# M3351 register map
File version: 1.0
Registers are 32-bit, read-write, reset 0x0 unless marked. A register's access mark holds for its fields unless they carry their own. Offsets are from the block's base; [hi:lo] are bit positions; {n}, {i} and the like mark numbered series; 'fields as' and 'values as' point back to an identical list.

## SCU — SCU Register Map
Base 0x4002F000
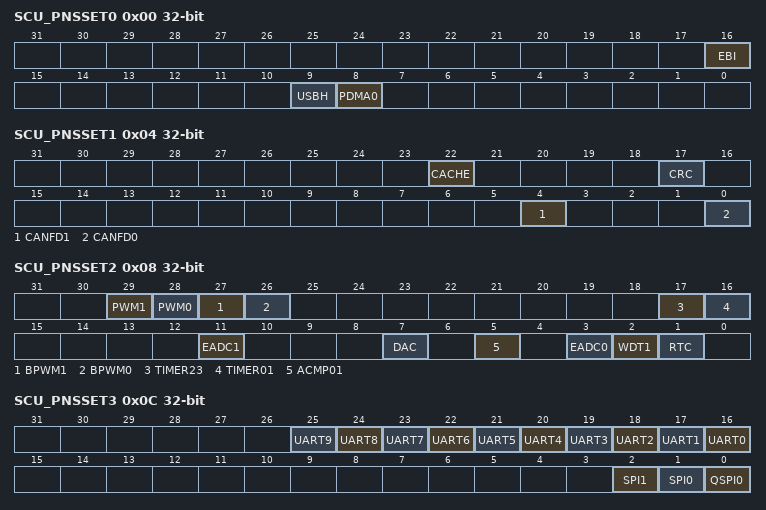
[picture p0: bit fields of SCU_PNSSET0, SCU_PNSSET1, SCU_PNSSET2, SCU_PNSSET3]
0x00 SCU_PNSSET0 — Peripheral Non-secure Attribution Set Register0 (0x4000_0000~0x4001_FFFF)
  [16] EBI — Set EBI to Non-secure State. Write 1 to set EBI to non-secure state. Note: This bit is write-protected by SCU_SCWP.
    0=EBI is a secure module (default); 1=EBI is a non-secure module
  [9] USBH — Set USBH to Non-secure State. Write 1 to set USBH to non-secure state. Note: This bit is write-protected by SCU_SCWP.
    0=USBH is a secure module (default); 1=USBH is a non-secure module
  [8] PDMA0 — Set PDMA0 to Non-secure State. Write 1 to set PDMA0 to non-secure state. Note: This bit is write-protected by SCU_SCWP.
    0=PDMA0 is a secure module (default); 1=PDMA0 is a non-secure module
0x04 SCU_PNSSET1 — Peripheral Non-secure Attribution Set Register1 (0x4002_0000~0x4003_FFFF)
  [22] CACHE — Set Cache Controller to Non-secure State. Write 1 to set Cache controller to non-secure state. Note: This bit is write-protected by SCU_SCWP.
    0=Cache controller is a secure module (default); 1=Cache controller is a non-secure module
  [17] CRC — Set CRC to Non-secure State. Write 1 to set CRC to non-secure state. Note: This bit is write-protected by SCU_SCWP.
    0=CRC is a secure module (default); 1=CRC is a non-secure module
  [4] CANFD1 — Set CANFD1 to Non-secure State. Write 1 to set CANFD1 to non-secure state. Note: This bit is write-protected by SCU_SCWP.
    0=CANFD1 is a secure module (default); 1=CANFD1 is a non-secure module
  [0] CANFD0 — Set CANFD0 to Non-secure State. Write 1 to set CANFD0 to non-secure state. Note: This bit is write-protected by SCU_SCWP.
    0=CANFD0 is a secure module (default); 1=CANFD0 is a non-secure module
0x08 SCU_PNSSET2 — Peripheral Non-secure Attribution Set Register2 (0x4004_0000~0x4005_FFFF)
  [29] PWM1 — Set PWM1 to Non-secure State. Write 1 to set PWM1 to non-secure state. Note: This bit is write-protected by SCU_SCWP.
    0=PWM1 is a secure module (default); 1=PWM1 is a non-secure module
  [28] PWM0 — Set PWM0 to Non-secure State. Write 1 to set PWM0 to non-secure state. Note: This bit is write-protected by SCU_SCWP.
    0=PWM0 is a secure module (default); 1=PWM0 is a non-secure module
  [27] BPWM1 — Set BPWM1 to Non-secure State. Write 1 to set BPWM1 to non-secure state. Note: This bit is write-protected by SCU_SCWP.
    0=BPWM1 is a secure module (default); 1=BPWM1 is a non-secure module
  [26] BPWM0 — Set BPWM0 to Non-secure State. Write 1 to set BPWM0 to non-secure state. Note: This bit is write-protected by SCU_SCWP.
    0=BPWM0 is a secure module (default); 1=BPWM0 is a non-secure module
  [17] TIMER23 — Set TIMER23 to Non-secure State. Write 1 to set TIMER23 to non-secure state. Note: This bit is write-protected by SCU_SCWP.
    0=TIMER23 is a secure module (default); 1=TIMER23 is a non-secure module
  [16] TIMER01 — Set TIMER01 to Non-secure State. Write 1 to set TIMER01 to non-secure state. Note: This bit is write-protected by SCU_SCWP.
    0=TIMER01 is a secure module (default); 1=TIMER01 is a non-secure module
  [11] EADC1 — Set EADC1 to Non-secure State. Write 1 to set EADC1 to non-secure state. Note: This bit is write-protected by SCU_SCWP.
    0=EADC1 is a secure module (default); 1=EADC1 is a non-secure module
  [7] DAC — Set DAC to Non-secure State. Write 1 to set DAC to non-secure state. Note: This bit is write-protected by SCU_SCWP.
    0=DAC is a secure module (default); 1=DAC is a non-secure module
  [5] ACMP01 — Set ACMP01 to Non-secure State. Write 1 to set ACMP01 to non-secure state. Note: This bit is write-protected by SCU_SCWP.
    0=ACMP01 is a secure module (default); 1=ACMP01 is a non-secure module
  [3] EADC0 — Set EADC0 to Non-secure State. Write 1 to set EADC0 to non-secure state. Note: This bit is write-protected by SCU_SCWP.
    0=EADC0 is a secure module (default); 1=EADC0 is a non-secure module
  [2] WDT1 — Set WDT1 to Non-secure State. Write 1 to set WDT1 to non-secure state. Note: This bit is write-protected by SCU_SCWP.
    0=WDT1 is a secure module (default); 1=WDT1 is a non-secure module
  [1] RTC — Set RTC to Non-secure State. Write 1 to set RTC to non-secure state. Note: This bit is write-protected by SCU_SCWP.
    0=RTC is a secure module (default); 1=RTC is a non-secure module
0x0C SCU_PNSSET3 — Peripheral Non-secure Attribution Set Register3 (0x4006_0000~0x4007_FFFF)
  [n+16] UART{n} (n=0..9) — Set UART{n} to Non-secure State. Write 1 to set UART{n} to non-secure state. Note: This bit is write-protected by SCU_SCWP.
    0=UART{n} is a secure module (default); 1=UART{n} is a non-secure module
  [2] SPI1 — Set SPI1 to Non-secure State. Write 1 to set SPI1 to non-secure state. Note: This bit is write-protected by SCU_SCWP.
    0=SPI1 is a secure module (default); 1=SPI1 is a non-secure module
  [1] SPI0 — Set SPI0 to Non-secure State. Write 1 to set SPI0 to non-secure state. Note: This bit is write-protected by SCU_SCWP.
    0=SPI0 is a secure module (default); 1=SPI0 is a non-secure module
  [0] QSPI0 — Set QSPI0 to Non-secure State. Write 1 to set QSPI0 to non-secure state. Note: This bit is write-protected by SCU_SCWP.
    0=QSPI0 is a secure module (default); 1=QSPI0 is a non-secure module
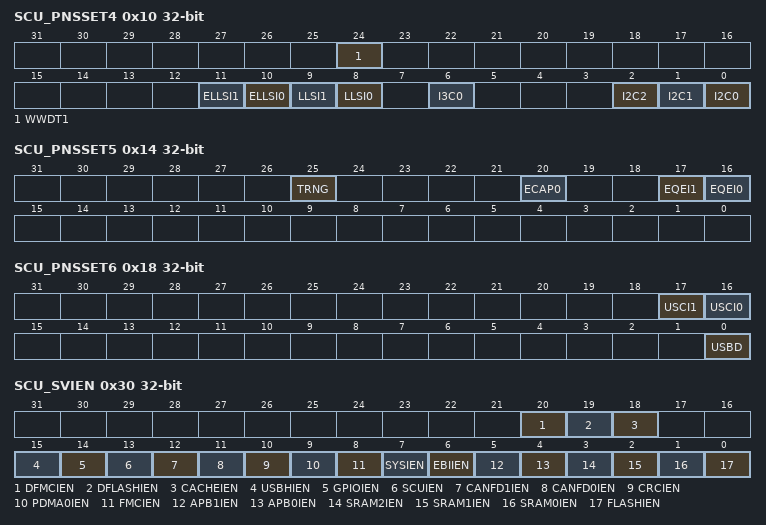
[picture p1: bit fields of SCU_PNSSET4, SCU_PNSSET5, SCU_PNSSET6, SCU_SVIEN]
0x10 SCU_PNSSET4 — Peripheral Non-secure Attribution Set Register4 (0x4008_0000~0x4009_FFFF)
  [24] WWDT1 — Set WWDT1 to Non-secure State. Write 1 to set WWDT1 to non-secure state. Note: This bit is write-protected by SCU_SCWP.
    0=WWDT1 is a secure module (default); 1=WWDT1 is a non-secure module
  [11] ELLSI1 — Set ELLSI1 to Non-secure State. Write 1 to set ELLSI1 to non-secure state. Note: This bit is write-protected by SCU_SCWP.
    0=ELLSI1 is a secure module (default); 1=ELLSI1 is a non-secure module
  [10] ELLSI0 — Set ELLSI0 to Non-secure State. Write 1 to set ELLSI0 to non-secure state. Note: This bit is write-protected by SCU_SCWP.
    0=ELLSI0 is a secure module (default); 1=ELLSI0 is a non-secure module
  [9] LLSI1 — Set LLSI1/3/5/7/9 to Non-secure State. Write 1 to set LLSI1/3/5/7/9 to non-secure state. Note: This bit is write-protected by SCU_SCWP.
    0=LLSI1/3/5/7/9 is a secure module (default); 1=LLSI1/3/5/7/9 is a non-secure module
  [8] LLSI0 — Set LLSI0/2/4/6/8 to Non-secure State. Write 1 to set LLSI0/2/4/6/8 to non-secure state. Note: This bit is write-protected by SCU_SCWP.
    0=LLSI0/2/4/6/8 is a secure module (default); 1=LLSI0/2/4/6/8 is a non-secure module
  [6] I3C0 — Set I3C0 to Non-secure State. Write 1 to set I3C0 to non-secure state. Note: This bit is write-protected by SCU_SCWP.
    0=I3C0 is a secure module (default); 1=I3C0 is a non-secure module
  [2] I2C2 — Set I2C2 to Non-secure State. Write 1 to set I2C2 to non-secure state. Note: This bit is write-protected by SCU_SCWP.
    0=I2C2 is a secure module (default); 1=I2C2 is a non-secure module
  [1] I2C1 — Set I2C1 to Non-secure State. Write 1 to set I2C1 to non-secure state. Note: This bit is write-protected by SCU_SCWP.
    0=I2C1 is a secure module (default); 1=I2C1 is a non-secure module
  [0] I2C0 — Set I2C0 to Non-secure State. Write 1 to set I2C0 to non-secure state. Note: This bit is write-protected by SCU_SCWP.
    0=I2C0 is a secure module (default); 1=I2C0 is a non-secure module
0x14 SCU_PNSSET5 — Peripheral Non-secure Attribution Set Register5 (0x400A_0000~0x400B_FFFF)
  [25] TRNG — Set TRNG to Non-secure State. Write 1 to set TRNG to non-secure state. Note: This bit is write-protected by SCU_SCWP.
    0=TRNG is a secure module (default); 1=TRNG is a non-secure module
  [20] ECAP0 — Set ECAP0 to Non-secure State. Write 1 to set ECAP0 to non-secure state. Note: This bit is write-protected by SCU_SCWP.
    0=ECAP0 is a secure module (default); 1=ECAP0 is a non-secure module
  [17] EQEI1 — Set EQEI1 to Non-secure State. Write 1 to set EQEI1 to non-secure state. Note: This bit is write-protected by SCU_SCWP.
    0=EQEI1 is a secure module (default); 1=EQEI1 is a non-secure module
  [16] EQEI0 — Set EQEI0 to Non-secure State. Write 1 to set EQEI0 to non-secure state. Note: This bit is write-protected by SCU_SCWP.
    0=EQEI0 is a secure module (default); 1=EQEI0 is a non-secure module
0x18 SCU_PNSSET6 — Peripheral Non-secure Attribution Set Register6 (0x400C_0000~0x400D_FFFF)
  [17] USCI1 — Set USCI1 to Non-secure State. Write 1 to set USCI1 to non-secure state. Note: This bit is write-protected by SCU_SCWP.
    0=USCI1 is a secure module (default); 1=USCI1 is a non-secure module
  [16] USCI0 — Set USCI0 to Non-secure State. Write 1 to set USCI0 to non-secure state. Note: This bit is write-protected by SCU_SCWP.
    0=USCI0 is a secure module (default); 1=USCI0 is a non-secure module
  [0] USBD — Set USBD to Non-secure State. Write 1 to set USBD to non-secure state. Note: This bit is write-protected by SCU_SCWP.
    0=USBD is a secure module (default); 1=USBD is a non-secure module
0x20 SCU_SRAMNSSET — SRAM Non-secure Attribution Set Register
  [19:0] SECn — Set SRAM Section n to Non-secure State. Write 1 to set SRAM section n to non-secure state. Size per section is 8 Kbytes. Secure SRAM section n is 0x2000_0000+0x2000*n to 0x2000_0000+0x2000*(n+1)-0x1. Non-secure SRAM section n is 0x3000_0000+0x2000*n to 0x3000_0000+0x2000*(n+1)-0x1. Note: This bit is write-protected by SCU_SCWP. Note: SEC16~SEC19 is only for ECC function disable.
    0=SRAM Section n is secure (default); 1=SRAM Section n is non-secure
0x2C SCU_FNSADDR ro reset not defined — Flash Non-secure Boundary Address Register
  [31:0] FNSADDR — Flash Non-secure Boundary Address. Indicate the base address of Non-secure region set in user configuration, NSCBA. Refer to FMC section for more details.
0x30 SCU_SVIEN — Security Violation Interrupt Enable Register
  [20] DFMCIEN — DFMC Security Violation Interrupt Enable Bit
    0=Interrupt triggered from security violation of DFMC Disabled; 1=Interrupt triggered from security violation of DFMC Enabled
  [19] DFLASHIEN — DFLASH Security Violation Interrupt Enable Bit
    0=Interrupt triggered from security violation of DFLASH Disabled; 1=Interrupt triggered from security violation of DFLASH Enabled
  [18] CACHEIEN — CACHE Controller Security Violation Interrupt Enable Bit
    0=Interrupt triggered from security violation of Cache Controller Disabled; 1=Interrupt triggered from security violation of Cache Controller Enabled
  [15] USBHIEN — USBH Security Violation Interrupt Enable Bit
    0=Interrupt triggered from security violation of USBH Disabled; 1=Interrupt triggered from security violation of USBH Enabled
  [14] GPIOIEN — GPIO Security Violation Interrupt Enable Bit
    0=Interrupt triggered from security violation of GPIO Disabled; 1=Interrupt triggered from security violation of GPIO Enabled
  [13] SCUIEN — SCU Security Violation Interrupt Enable Bit
    0=Interrupt triggered from security violation of SCU Disabled; 1=Interrupt triggered from security violation of SCU Enabled
  [12] CANFD1IEN — CANFD1 Security Violation Interrupt Enable Bit
    0=Interrupt triggered from security violation of CANFD1 Disabled; 1=Interrupt triggered from security violation of CANFD1 Enabled
  [11] CANFD0IEN — CANFD0 Security Violation Interrupt Enable Bit
    0=Interrupt triggered from security violation of CANFD0 Disabled; 1=Interrupt triggered from security violation of CANFD0 Enabled
  [10] CRCIEN — CRC Security Violation Interrupt Enable Bit
    0=Interrupt triggered from security violation of CRC Disabled; 1=Interrupt triggered from security violation of CRC Enabled
  [9] PDMA0IEN — PDMA0 Security Violation Interrupt Enable Bit
    0=Interrupt triggered from security violation of PDMA0 Disabled; 1=Interrupt triggered from security violation of PDMA0 Enabled
  [8] FMCIEN — FMC Security Violation Interrupt Enable Bit
    0=Interrupt triggered from security violation of FMC Disabled; 1=Interrupt triggered from security violation of FMC Enabled
  [7] SYSIEN — SYS Security Violation Interrupt Enable Bit
    0=Interrupt triggered from security violation of SYS Disabled; 1=Interrupt triggered from security violation of SYS Enabled
  [6] EBIIEN — EBI Security Violation Interrupt Enable Bit
    0=Interrupt triggered from security violation of EBI Disabled; 1=Interrupt triggered from security violation of EBI Enabled
  [5] APB1IEN — APB1 Security Violation Interrupt Enable Bit
    0=Interrupt triggered from security violation of APB1 Disabled; 1=Interrupt triggered from security violation of APB1 Enabled
  [4] APB0IEN — APB0 Security Violation Interrupt Enable Bit
    0=Interrupt triggered from security violation of APB0 Disabled; 1=Interrupt triggered from security violation of APB0 Enabled
  [3] SRAM2IEN — SRAM2 Security Violation Interrupt Enable Bit. Note: this bit is only for ECC function disable.
    0=Interrupt triggered from security violation of SRAM2 Disabled; 1=Interrupt triggered from security violation of SRAM2 Enabled
  [2] SRAM1IEN — SRAM1 Security Violation Interrupt Enable Bit
    0=Interrupt triggered from security violation of SRAM1 Disabled; 1=Interrupt triggered from security violation of SRAM1 Enabled
  [1] SRAM0IEN — SRAM0 Security Violation Interrupt Enable Bit
    0=Interrupt triggered from security violation of SRAM0 Disabled; 1=Interrupt triggered from security violation of SRAM0 Enabled
  [0] FLASHIEN — FLASH Security Violation Interrupt Enable Bit
    0=Interrupt triggered from security violation of FLASH Disabled; 1=Interrupt triggered from security violation of FLASH Enabled
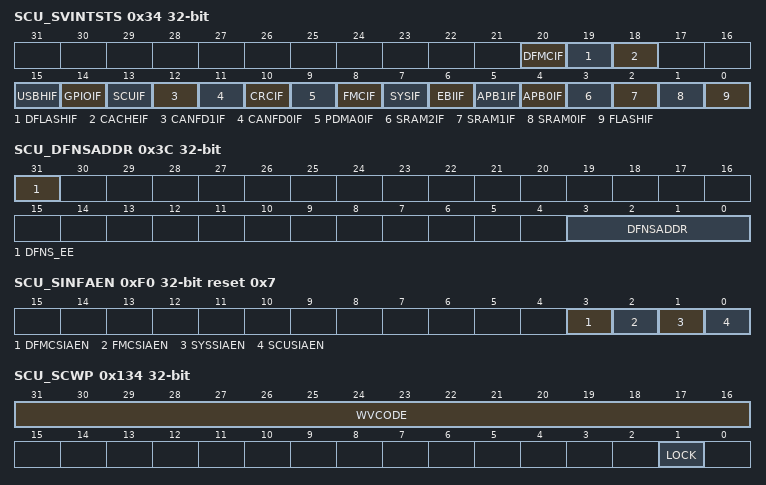
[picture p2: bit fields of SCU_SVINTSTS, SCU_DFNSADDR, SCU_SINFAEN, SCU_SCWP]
0x34 SCU_SVINTSTS — Security Violation Interrupt Status Register
  [20] DFMCIF — DFMC Security Violation Interrupt Status. Note: Write 1 to clear the interrupt flag.
    0=No DFMC violation interrupt event; 1=There is at least DFMC violation interrupt event
  [19] DFLASHIF — Data FLASH Security Violation Interrupt Status. Note: Write 1 to clear the interrupt flag.
    0=No Data FLASH violation interrupt event; 1=There is at least a Data FLASH violation interrupt event
  [18] CACHEIF — CACHE Controller Security Violation Interrupt Status. Note: Write 1 to clear the interrupt flag.
    0=No Cache Controller violation interrupt event; 1=There is at least a Cache Controller violation interrupt event
  [15] USBHIF — USBH Security Violation Interrupt Status. Note: Write 1 to clear the interrupt flag.
    0=No USBH violation interrupt event; 1=There is at least a USBH violation interrupt event
  [14] GPIOIF — GPIO Security Violation Interrupt Status. Note: Write 1 to clear the interrupt flag.
    0=No GPIO violation interrupt event; 1=There is at least a GPIO violation interrupt event
  [13] SCUIF — SCU Security Violation Interrupt Status. Note: Write 1 to clear the interrupt flag.
    0=No SCU violation interrupt event; 1=There is at least a SCU violation interrupt event
  [12] CANFD1IF — CANFD1 Security Violation Interrupt Status. Note: Write 1 to clear the interrupt flag.
    0=No CANFD1 violation interrupt event; 1=There is at least a CANFD1 violation interrupt event
  [11] CANFD0IF — CANFD0 Security Violation Interrupt Status. Note: Write 1 to clear the interrupt flag.
    0=No CANFD0 violation interrupt event; 1=There is at least a CANFD0 violation interrupt event
  [10] CRCIF — CRC Security Violation Interrupt Status. Note: Write 1 to clear the interrupt flag.
    0=No CRC violation interrupt event; 1=There is at least CRC violation interrupt event
  [9] PDMA0IF — PDMA0 Security Violation Interrupt Status. Note: Write 1 to clear the interrupt flag.
    0=No PDMA0 violation interrupt event; 1=There is at least a PDMA0 violation interrupt event
  [8] FMCIF — FMC Security Violation Interrupt Status. Note: Write 1 to clear the interrupt flag.
    0=No FMC violation interrupt event; 1=There is at least FMC violation interrupt event
  [7] SYSIF — SYS Security Violation Interrupt Status. Note: Write 1 to clear the interrupt flag.
    0=No SYS violation interrupt event; 1=There is at least SYS violation interrupt event
  [6] EBIIF — EBI Security Violation Interrupt Status. Note: Write 1 to clear the interrupt flag.
    0=No EBI violation interrupt event; 1=There is at least EBI violation interrupt event
  [5] APB1IF — APB1 Security Violation Interrupt Status. Note: Write 1 to clear the interrupt flag.
    0=No APB1 violation interrupt event; 1=There is at least a APB1 violation interrupt event
  [4] APB0IF — APB0 Security Violation Interrupt Status. Note: Write 1 to clear the interrupt flag.
    0=No APB0 violation interrupt event; 1=There is at least a APB0 violation interrupt event
  [3] SRAM2IF — SRAM2 Security Violation Interrupt Status. Note: Write 1 to clear the interrupt flag. Note: this bit is only for ECC function disable.
    0=No SRAM2 violation interrupt event; 1=There is at least a SRAM2 violation interrupt event
  [2] SRAM1IF — SRAM1 Security Violation Interrupt Status. Note: Write 1 to clear the interrupt flag.
    0=No SRAM1 violation interrupt event; 1=There is at least a SRAM1 violation interrupt event
  [1] SRAM0IF — SRAM0 Security Violation Interrupt Status. Note: Write 1 to clear the interrupt flag.
    0=No SRAM0 violation interrupt event; 1=There is at least a SRAM0 violation interrupt event
  [0] FLASHIF — FLASH Security Violation Interrupt Status. Note: Write 1 to clear the interrupt flag.
    0=No FLASH violation interrupt event; 1=There is at least a FLASH violation interrupt event
0x3C SCU_DFNSADDR ro reset not defined — Data Flash Non-secure Boundary Address Register
  [31] DFNS_EE — DFMC EEPROM Non-secure State. Write 1 to set USCI1 to non-secure state.
    0=DFMC EEPROM is a secure module; 1=DFMC EEPROM is a non-secure module
  [3:0] DFNSADDR — DFlash Non-secure Boundary Address. Indicate the base address of Non-secure region set in user configuration, NSCBA. Refer to DFMC section for more details.
0x40 SCU_FLASHVSRC ro (reset mask 0xFFFFFFF0) — FLASH Security Policy Violation Source
  [3:0] MASTER — Master Violating Security Policy. Indicate which master invokes the security violation. . Others are undefined.
    2=Core processor; 3=PDMA0; 4=USB Host Controller (USBH); 5=CRC
0x44 SCU_FLASHVA ro reset not defined — FLASH Violation Address
  [31:0] VIOADDR — Violation Address. Indicate the target address of the access, which invokes the security violation.
0x48 SCU_SRAM0VSRC ro (reset mask 0xFFFFFFF0) — SRAM0 Security Policy Violation Source
  fields as SCU_FLASHVSRC
0x4C SCU_SRAM0VA ro reset not defined — SRAM0 Violation Address
  fields as SCU_FLASHVA
0x50 SCU_SRAM1VSRC ro (reset mask 0xFFFFFFF0) — SRAM1 Security Policy Violation Source
  fields as SCU_FLASHVSRC
0x54 SCU_SRAM1VA ro reset not defined — SRAM1 Violation Address
  fields as SCU_FLASHVA
0x58 SCU_SRAM2VSRC ro (reset mask 0xFFFFFFF0) — SRAM2 Security Policy Violation Source. Note: this register is only for ECC function disable.
  fields as SCU_FLASHVSRC
0x5C SCU_SRAM2VA ro reset not defined — SRAM2 Violation Address. Note: this register is only for ECC function disable.
  fields as SCU_FLASHVA
0x60 SCU_APB0VSRC ro (reset mask 0xFFFFFFF0) — APB0 Security Policy Violation Source
  fields as SCU_FLASHVSRC
0x64 SCU_APB0VA ro reset not defined — APB0 Violation Address
  fields as SCU_FLASHVA
0x68 SCU_APB1VSRC ro (reset mask 0xFFFFFFF0) — APB1 Security Policy Violation Source
  fields as SCU_FLASHVSRC
0x6C SCU_APB1VA ro reset not defined — APB1 Violation Address
  fields as SCU_FLASHVA
0x70 SCU_EBIVSRC ro (reset mask 0xFFFFFFF0) — EBI Security Policy Violation Source
  fields as SCU_FLASHVSRC
0x74 SCU_EBIVA ro reset not defined — EBI Violation Address
  fields as SCU_FLASHVA
0x78 SCU_SYSVSRC ro (reset mask 0xFFFFFFF0) — SYS Security Policy Violation Source
  fields as SCU_FLASHVSRC
0x7C SCU_SYSVA ro reset not defined — SYS Violation Address
  fields as SCU_FLASHVA
0x80 SCU_FMCVSRC ro (reset mask 0xFFFFFFF0) — FMC Security Policy Violation Source
  fields as SCU_FLASHVSRC
0x84 SCU_FMCVA ro reset not defined — FMC Violation Address
  fields as SCU_FLASHVA
0x88 SCU_PDMA0VSRC ro (reset mask 0xFFFFFFF0) — PDMA0 Security Policy Violation Source
  fields as SCU_FLASHVSRC
0x8C SCU_PDMA0VA ro reset not defined — PDMA0 Violation Address
  fields as SCU_FLASHVA
0x90 SCU_CRCVSRC ro (reset mask 0xFFFFFFF0) — CRC Security Policy Violation Source
  fields as SCU_FLASHVSRC
0x94 SCU_CRCVA ro reset not defined — CRC Violation Address
  fields as SCU_FLASHVA
0x98 SCU_CANFD0VSRC ro (reset mask 0xFFFFFFF0) — CANFD0 Security Policy Violation Source
  fields as SCU_FLASHVSRC
0x9C SCU_CANFD0VA ro reset not defined — CANFD0 Violation Address
  fields as SCU_FLASHVA
0xA0 SCU_CANFD1VSRC ro (reset mask 0xFFFFFFF0) — CANFD1 Security Policy Violation Source
  fields as SCU_FLASHVSRC
0xA4 SCU_CANFD1VA ro reset not defined — CANFD1 Violation Address
  fields as SCU_FLASHVA
0xA8 SCU_SCUVSRC ro (reset mask 0xFFFFFFF0) — SCU Security Policy Violation Source
  fields as SCU_FLASHVSRC
0xAC SCU_SCUVA ro reset not defined — SCU Violation Address
  fields as SCU_FLASHVA
0xB0 SCU_GPIOVSRC ro (reset mask 0xFFFFFFF0) — GPIO Security Policy Violation Source
  fields as SCU_FLASHVSRC
0xB4 SCU_GPIOVA ro reset not defined — GPIO Violation Address
  fields as SCU_FLASHVA
0xBC SCU_USBHVA ro reset not defined — USBH Violation Address
  fields as SCU_FLASHVA
0xC0 SCU_USBHVSRC ro (reset mask 0xFFFFFFF0) — USBH Security Policy Violation Source
  fields as SCU_FLASHVSRC
0xD0 SCU_CACHEVSRC ro (reset mask 0xFFFFFFF0) — CACHE Controller Security Policy Violation Source
  fields as SCU_FLASHVSRC
0xD4 SCU_CACHEVA ro reset not defined — CACHE Controller Violation Address
  fields as SCU_FLASHVA
0xD8 SCU_DFLASHVSRC ro (reset mask 0xFFFFFFF0) — DFLASH Security Policy Violation Source
  fields as SCU_FLASHVSRC
0xDC SCU_DFLASHVA ro reset not defined — DFLASH Violation Address
  fields as SCU_FLASHVA
0xE0 SCU_DFMCVSRC ro (reset mask 0xFFFFFFF0) — DFMC Security Policy Violation Source
  fields as SCU_FLASHVSRC
0xE4 SCU_DFMCVA ro reset not defined — DFMC Violation Address
  fields as SCU_FLASHVA
0xF0 SCU_SINFAEN reset 0x7 — Shared Information Access Enable Register
  [3] DFMCSIAEN — DFMC Shared Information Access Enable Bit
    0=Non-secure CPU access DFMC Shared information Disabled; 1=Non-secure CPU access DFMC Shared information Enabled
  [2] FMCSIAEN — FMC Shared Information Access Enable Bit
    0=Non-secure CPU access FMC Shared information Disabled; 1=Non-secure CPU access FMC Shared information Enabled
  [1] SYSSIAEN — SYS Shared Information Access Enable Bit. Note: Include clock information.
    0=Non-secure CPU access SYS Shared information Disabled; 1=Non-secure CPU access SYS Shared information Enabled
  [0] SCUSIAEN — SCU Shared Information Access Enable Bit
    0=Non-secure CPU access SCU Shared information Disabled; 1=Non-secure CPU access SCU Shared information Enabled
0x134 SCU_SCWP — Security Configuration Write Protect Register
  [31:16] WVCODE — Write Verify Code. Read operation: Reserved, all zeros. Write operation:
    0x475A=The write verify code, 0x475A, is needed to do a valid write to SCU_SCWP
  [1] LOCK — Enable Write Protect Lock Bit. Note: This bit cannot be cleared to 0 without a system-level reset after set to one.
    0=Write Protect lock Disabled; 1=Write Protect Enabled and locked
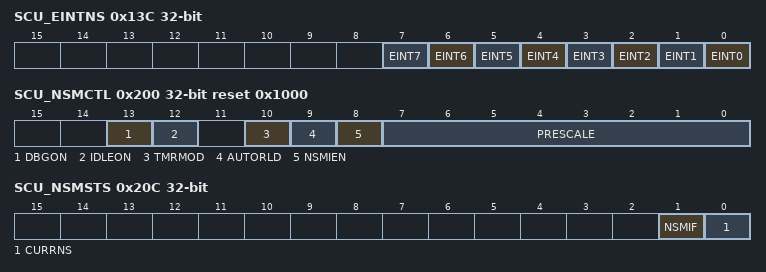
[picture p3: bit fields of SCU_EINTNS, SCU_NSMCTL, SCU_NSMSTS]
0x13C SCU_EINTNS — EINT Non-secure Attribution Set Register
  [n] EINT{n} (n=0..7) — Set EINT{n} to Non-secure State. Note: This bit is write-protected by SCU_SCWP.
    0=EINT{n} is a secure module (default); 1=EINT{n} is a non-secure module
0x140 SCU_IONSSET0 — I/O Non-secure Attribution Set Register0
  [15:0] PA — Set GPIO Port A to Non-secure State. Write 1 to set PA to non-secure state. Each bit configures one pin in GPIO port A. Note: This bit is write-protected by SCU_SCWP.
    0=GPIO port A is secure (default); 1=GPIO port A is non-secure
0x144 SCU_IONSSET1 — I/O Non-secure Attribution Set Register1
  [15:0] PB — Set GPIO Port B to Non-secure State. Write 1 to set PB to non-secure state. Each bit configures one pin in GPIO port B. Note: This bit is write-protected by SCU_SCWP.
    0=GPIO port B is secure (default); 1=GPIO port B is non-secure
0x148 SCU_IONSSET2 — I/O Non-secure Attribution Set Register2
  [15:0] PC — Set GPIO Port C to Non-secure State. Write 1 to set PC to non-secure state. Each bit configures one pin in GPIO port C. Note: This bit is write-protected by SCU_SCWP.
    0=GPIO port C is secure (default); 1=GPIO port C is non-secure
0x14C SCU_IONSSET3 — I/O Non-secure Attribution Set Register3
  [15:0] PD — Set GPIO Port D to Non-secure State. Write 1 to set PD to non-secure state. Each bit configures one pin in GPIO port D. Note: This bit is write-protected by SCU_SCWP.
    0=GPIO port D is secure (default); 1=GPIO port D is non-secure
0x150 SCU_IONSSET4 — I/O Non-secure Attribution Set Register4
  [15:0] PE — Set GPIO Port E to Non-secure State. Write 1 to set PE to non-secure state. Each bit configures one pin in GPIO port E. Note: This bit is write-protected by SCU_SCWP.
    0=GPIO port E is secure (default); 1=GPIO port E is non-secure
0x154 SCU_IONSSET5 — I/O Non-secure Attribution Set Register5
  [15:0] PF — Set GPIO Port F to Non-secure State. Write 1 to set PF to non-secure state. Each bit configures one pin in GPIO port F. Note: This bit is write-protected by SCU_SCWP.
    0=GPIO port F is secure (default); 1=GPIO port F is non-secure
0x158 SCU_IONSSET6 — I/O Non-secure Attribution Set Register6
  [15:0] PG — Set GPIO Port G to Non-secure State. Write 1 to set PG to non-secure state. Each bit configures one pin in GPIO port G. Note: This bit is write-protected by SCU_SCWP.
    0=GPIO port G is secure (default); 1=GPIO port G is non-secure
0x15C SCU_IONSSET7 — I/O Non-secure Attribution Set Register7
  [15:0] PH — Set GPIO Port H to Non-secure State. Write 1 to set PH to non-secure state. Each bit configures one pin in GPIO port H. Note: This bit is write-protected by SCU_SCWP.
    0=GPIO port H is secure (default); 1=GPIO port H is non-secure
0x200 SCU_NSMCTL reset 0x1000 — Non-secure State Monitor Control Register
  [13] DBGON — Monitor Counter Keep Counting When the Chip Is in Debug Mode Enable Bit
    0=The counter will be halted when the core processor is halted by ICE. (default); 1=The counter will keep counting when the core processor is halted by ICE
  [12] IDLEON — Monitor Counter Keep Counting When the Chip Is in Idle Mode Enable Bit. Note: In monitor mode, the counter is always halted when the core processor is in secure state.
    0=The counter will be halted when the chip is in idle mode; 1=The counter will keep counting when the chip is in idle mode. (default)
  [10] TMRMOD — Non-secure Monitor Mode Enable Bit
    0=Monitor mode. The counter will count down when the core processor is in non-secure state. (default); 1=Free-counting mode. The counter will keep counting no matter the core processor is in secure or non-secure state
  [9] AUTORLD — Auto Reload Non-secure State Monitor Counter When CURRNS Changing to 1
    0=Disable clearing non-secure state monitor counter automatically (default); 1=Enable clearing non-secure state monitor counter automatically when the core processor changes from secure state to non-secure state
  [8] NSMIEN — Non-secure State Monitor Interrupt Enable Bit
    0=Non-secure state monitor interrupt Disabled; 1=Non-secure state monitor interrupt Enabled
  [7:0] PRESCALE — Pre-scale Value of Non-secure State Monitor Counter
    0=Counter Disabled
0x204 SCU_NSMLOAD reset 0xFFFFFF — Non-secure State Monitor Reload Value Register
  [23:0] RELOAD — Reload Value for Non-secure State Monitor Counter. The RELOAD value will be reloaded to the counter whenever the counter counts down to 0.
0x208 SCU_NSMVAL reset 0xFFFFFF — Non-secure State Monitor Counter Value Register
  [23:0] VALUE — Counter Value of Non-secure State Monitor Counter. A write of any value clears the VALUE to 0 and also clears NSMIF(SCU_NSMSTS[1]).
0x20C SCU_NSMSTS — Non-secure State Monitor Status Register
  [1] NSMIF — Non-secure State Monitor Interrupt Flag. Note: This bit is cleared by writing 1.
    0=Counter does not count down to 0 since the last NSMIF has been cleared; 1=Counter counts down to 0
  [0] CURRNS — Current Core Processor Secure/Non-secure State (Read Only). Note: This bit can be used to monitor the current secure/non-secure state of the core processor, even if the non-secure state monitor counter is disabled.
    0=Core processor is in secure state; 1=Core processor is in non-secure state
